# STM32L552 register map
File version: 1.0
CPU: CM33 r0p1, little endian, MPU, FPU, 3 interrupt priority bits
Registers are 32-bit, read-write, reset 0x0 unless marked. A register's access mark holds for its fields unless they carry their own. Offsets are from the block's base; [hi:lo] are bit positions; {n}, {i} and the like mark numbered series; 'fields as' and 'values as' point back to an identical list.

## SYSCFG — System configuration controller
Base 0x40010000
Same registers: SEC_SYSCFG 0x50010000
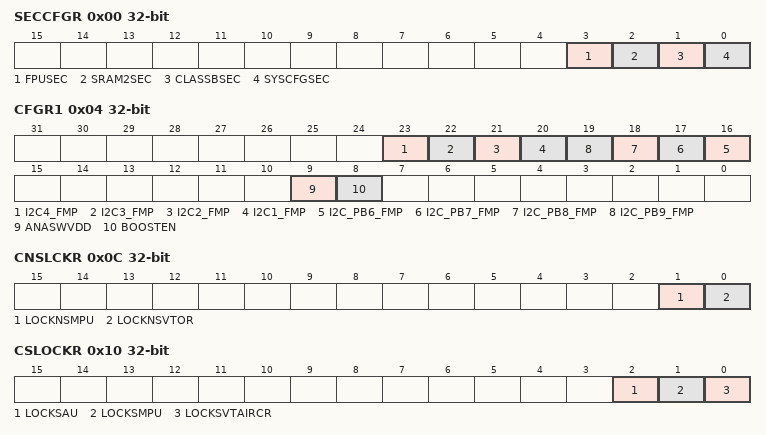
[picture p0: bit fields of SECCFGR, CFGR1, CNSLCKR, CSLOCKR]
0x00 SECCFGR — SYSCFG secure configuration register
  [3] FPUSEC
  [2] SRAM2SEC — SRAM2 security
  [1] CLASSBSEC — ClassB security
  [0] SYSCFGSEC — SYSCFG clock control security
0x04 CFGR1 — configuration register 1
  [23] I2C4_FMP
  [22] I2C3_FMP — I2C3 Fast-mode Plus driving capability activation
  [21] I2C2_FMP — I2C2 Fast-mode Plus driving capability activation
  [20] I2C1_FMP — I2C1 Fast-mode Plus driving capability activation
  [n+10] I2C_PB{n}_FMP (n=6..9) — Fast-mode Plus (Fm+) driving capability activation on PB{n}
  [9] ANASWVDD — GPIO analog switch control voltage selection
  [8] BOOSTEN — I/O analog switch voltage booster enable
0x08 FPUIMR reset 0x1F — FPU interrupt mask register
  [5:0] FPU_IE — Floating point unit interrupts enable bits
0x0C CNSLCKR — SYSCFG CPU non-secure lock register
  [1] LOCKNSMPU — Non-secure MPU registers lock
  [0] LOCKNSVTOR — VTOR_NS register lock
0x10 CSLOCKR — SYSCFG CPU secure lock register
  [2] LOCKSAU, [1] LOCKSMPU, [0] LOCKSVTAIRCR
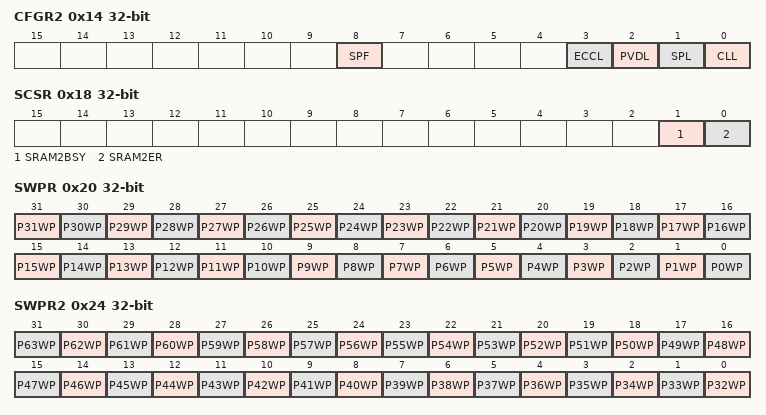
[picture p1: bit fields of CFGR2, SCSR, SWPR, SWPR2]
0x14 CFGR2 access per field
  [8] SPF rw — SRAM2 parity error flag
  [3] ECCL wo — ECC Lock
  [2] PVDL wo — PVD lock enable bit
  [1] SPL wo — SRAM2 parity lock bit
  [0] CLL wo — LOCKUP (hardfault) output enable bit
0x18 SCSR access per field
  [1] SRAM2BSY ro — SRAM2 busy by erase operation
  [0] SRAM2ER rw — SRAM2 Erase
0x1C SKR wo
  [7:0] KEY — SRAM2 write protection key for software erase
0x20 SWPR wo
  [31] P31WP — SRAM2 page 31 write protection
  [n] P{n}WP (n=0..30)
0x24 SWPR2 wo
  [n-32] P{n}WP (n=32..63)
0x2C RSSCMDR
  [7:0] RSSCMD — RSS commands

## TAMP — Tamper and backup registers
Base 0x40003400
Same registers: SEC_TAMP 0x50003400
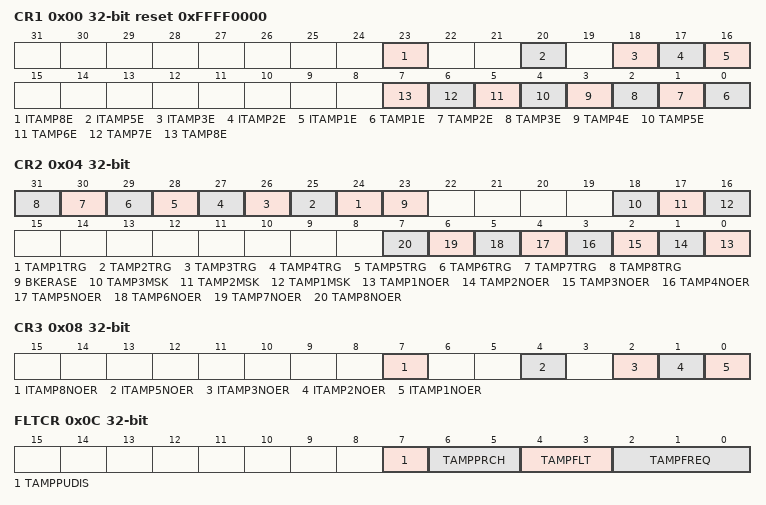
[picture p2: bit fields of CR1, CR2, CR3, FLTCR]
0x00 CR1 reset 0xFFFF0000 — control register 1
  [23] ITAMP8E — ITAMP5E
  [20] ITAMP5E
  [18] ITAMP3E
  [17] ITAMP2E
  [16] ITAMP1E
  [n-1] TAMP{n}E (n=1..8)
0x04 CR2 — control register 2
  [n+23] TAMP{n}TRG (n=1..8), [23] BKERASE, [18] TAMP3MSK, [17] TAMP2MSK, [16] TAMP1MSK, [n-1] TAMP{n}NOER (n=1..8)
0x08 CR3 — control register 3
  [7] ITAMP8NOER, [4] ITAMP5NOER, [2] ITAMP3NOER, [1] ITAMP2NOER, [0] ITAMP1NOER
0x0C FLTCR — TAMP filter control register
  [7] TAMPPUDIS, [6:5] TAMPPRCH, [4:3] TAMPFLT, [2:0] TAMPFREQ
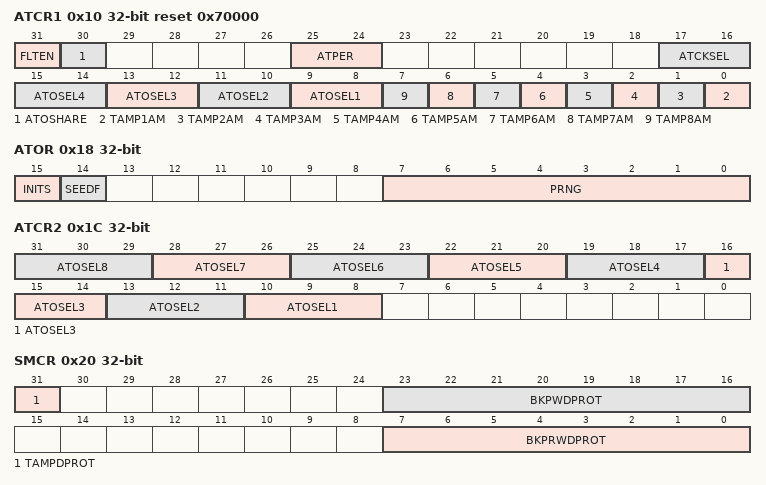
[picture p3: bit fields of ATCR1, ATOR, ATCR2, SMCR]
0x10 ATCR1 reset 0x70000 — TAMP active tamper control register 1
  [31] FLTEN, [30] ATOSHARE, [25:24] ATPER, [17:16] ATCKSEL, [2n+7:2n+6] ATOSEL{n} (n=1..4), [n-1] TAMP{n}AM (n=1..8)
0x14 ATSEEDR wo — TAMP active tamper seed register
  [31:0] SEED — Pseudo-random generator seed value
0x18 ATOR ro — TAMP active tamper output register
  [15] INITS — Active tamper initialization status
  [14] SEEDF — Seed running flag
  [7:0] PRNG — Pseudo-random generator value
0x1C ATCR2 — TAMP active tamper control register 2
  [3n+7:3n+5] ATOSEL{n} (n=1..8)
0x20 SMCR — TAMP secure mode register
  [31] TAMPDPROT — Tamper protection
  [23:16] BKPWDPROT — Backup registers write protection offset
  [7:0] BKPRWDPROT — Backup registers read/write protection offset
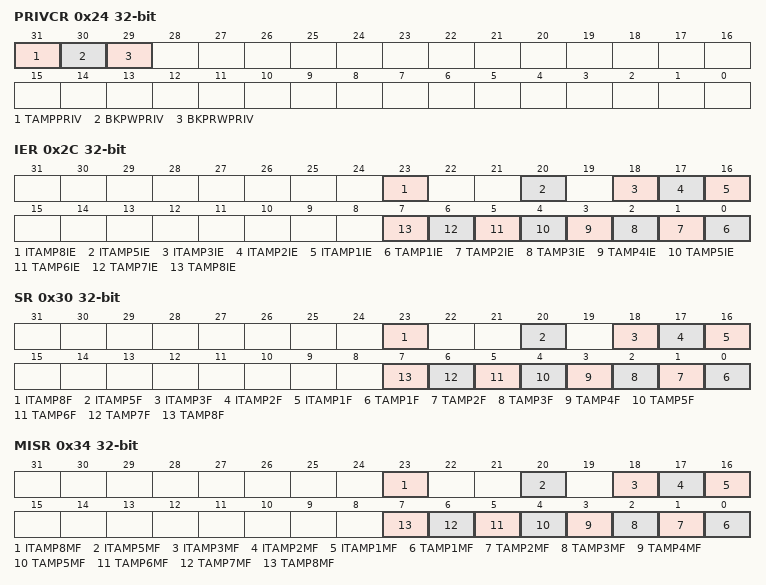
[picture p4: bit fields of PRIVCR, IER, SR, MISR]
0x24 PRIVCR — TAMP privilege mode control register
  [31] TAMPPRIV — Tamper privilege protection
  [30] BKPWPRIV — Backup registers zone 2 privilege protection
  [29] BKPRWPRIV — Backup registers zone 1 privilege protection
0x2C IER — TAMP interrupt enable register
  [23] ITAMP8IE, [20] ITAMP5IE, [18] ITAMP3IE, [17] ITAMP2IE, [16] ITAMP1IE, [n-1] TAMP{n}IE (n=1..8)
0x30 SR ro — TAMP status register
  [23] ITAMP8F, [20] ITAMP5F, [18] ITAMP3F, [17] ITAMP2F, [16] ITAMP1F, [n-1] TAMP{n}F (n=1..8)
0x34 MISR ro — TAMP masked interrupt status register
  [23] ITAMP8MF, [20] ITAMP5MF, [18] ITAMP3MF, [17] ITAMP2MF, [16] ITAMP1MF, [n-1] TAMP{n}MF (n=1..8)
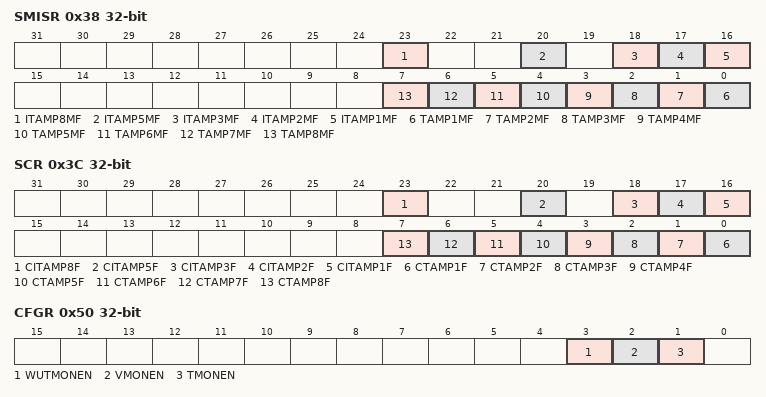
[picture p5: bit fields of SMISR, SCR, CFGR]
0x38 SMISR ro — TAMP secure masked interrupt status register
  fields as MISR
0x3C SCR wo — TAMP status clear register
  [23] CITAMP8F, [20] CITAMP5F, [18] CITAMP3F, [17] CITAMP2F, [16] CITAMP1F, [n-1] CTAMP{n}F (n=1..8)
0x40 COUNTR ro — TAMP monotonic counter register
  [31:0] COUNT
0x50 CFGR — TAMP configuration register
  [3] WUTMONEN, [2] VMONEN, [1] TMONEN
{0x100+4i} BKP{i}R (i=0..31) — TAMP backup register
  [31:0] BKP

## TIM6 — General-purpose-timers
Base 0x40001000
Same registers: TIM7 0x40001400, SEC_TIM6 0x50001000, SEC_TIM7 0x50001400
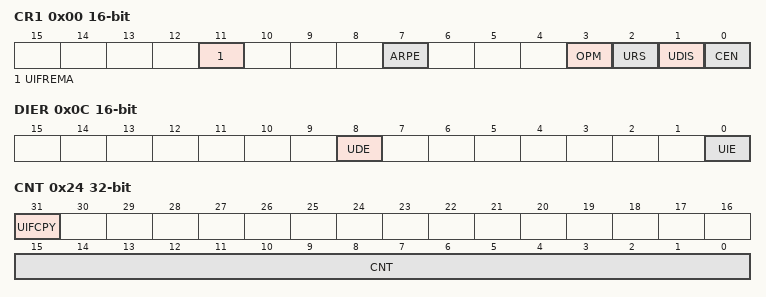
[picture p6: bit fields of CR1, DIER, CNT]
0x00 CR1 16-bit — control register 1
  [11] UIFREMA — UIF status bit remapping
  [7] ARPE — Auto-reload preload enable
    0=Disabled (TIMx_APRR register is not buffered); 1=Enabled (TIMx_APRR register is buffered)
  [3] OPM — One-pulse mode
    0=Disabled (Counter is not stopped at update event); 1=Enabled (Counter stops counting at the next update event (clearing the CEN bit))
  [2] URS — Update request source
    0=AnyEvent (Any of counter overflow/underflow, setting UG, or update through slave mode, generates an update interrupt or DMA request); 1=CounterOnly (Only counter overflow/underflow generates an update interrupt or DMA request)
  [1] UDIS — Update disable
    0=Enabled (Update event enabled); 1=Disabled (Update event disabled)
  [0] CEN — Counter enable
    0=Disabled (Counter disabled); 1=Enabled (Counter enabled)
0x04 CR2 16-bit — control register 2
  [6:4] MMS — Master mode selection
    0=Reset (Use UG bit from TIMx_EGR register); 1=Enable (Use CNT bit from TIMx_CEN register); 2=Update (Use the update event)
0x0C DIER 16-bit — DMA/Interrupt enable register
  [8] UDE — Update DMA request enable
    0=Disabled (Update DMA request disabled); 1=Enabled (Update DMA request enabled)
  [0] UIE — Update interrupt enable
    0=Disabled (Update interrupt disabled); 1=Enabled (Update interrupt enabled)
0x10 SR 16-bit — status register
  [0] UIF write-0-clears — Update interrupt flag
    on read: 0=NoUpdateOccurred; 1=UpdatePending (Update interrupt pending) | on write: 0=Clear flag
0x14 EGR wo — event generation register
  [0] UG — Update generation
    1=Update (Re-initializes the timer counter and generates an update of the registers.)
0x24 CNT — counter
  [31] UIFCPY — UIFCPY or Res
  [15:0] CNT
0x24 CNT16 16-bit (alternate view of CNT) — 16-bit counter register
  [15:0] CNT — counter value
0x28 PSC 16-bit — prescaler
  [15:0] PSC — Prescaler value
0x2C ARR 16-bit reset 0xFFFF — auto-reload register
  [15:0] ARR — ARR_bit0

## VREFBUF — Voltage reference buffer
Base 0x40010030
Same registers: SEC_VREFBUF 0x50010030
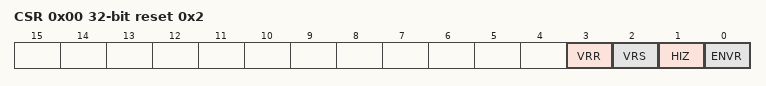
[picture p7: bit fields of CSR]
0x00 CSR access per field reset 0x2 — VREF control and status register
  [3] VRR ro — Voltage reference buffer ready
  [2] VRS rw — Voltage reference scale
  [1] HIZ rw — High impedance mode
  [0] ENVR rw — Voltage reference buffer enable
0x04 CCR — calibration control register
  [5:0] TRIM — Trimming code

## WWDG — System window watchdog
Base 0x40002C00
Same registers: SEC_WWDG 0x50002C00
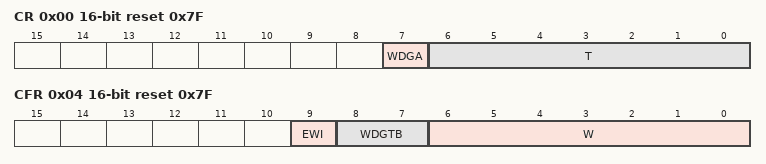
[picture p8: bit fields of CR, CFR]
0x00 CR 16-bit reset 0x7F — Control register
  [7] WDGA — Activation bit
    0=Disabled (Watchdog disabled); 1=Enabled (Watchdog enabled)
  [6:0] T — 7-bit counter (MSB to LSB)
0x04 CFR 16-bit reset 0x7F — Configuration register
  [9] EWI — Early wakeup interrupt
    on write: 1=Enable (interrupt occurs whenever the counter reaches the value 0x40)
  [8:7] WDGTB — Timer base
    0=Div1 (Counter clock (PCLK1 div 4096) div 1); 1=Div2 (Counter clock (PCLK1 div 4096) div 2); 2=Div4 (Counter clock (PCLK1 div 4096) div 4); 3=Div8 (Counter clock (PCLK1 div 4096) div 8)
  [6:0] W — 7-bit window value
0x08 SR 16-bit — Status register
  [0] EWIF write-0-clears — Early wakeup interrupt flag
    on read: 0=Finished (The EWI Interrupt Service Routine has been serviced); 1=Pending (The EWI Interrupt Service Routine has been triggered) | on write: 0=Finished (The EWI Interrupt Service Routine has been serviced)
